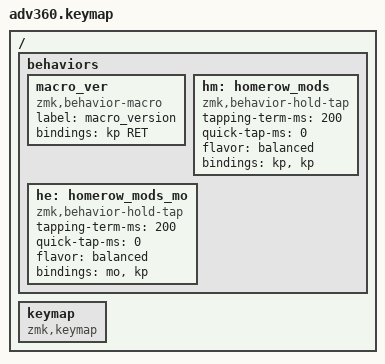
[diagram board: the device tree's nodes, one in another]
#include <behaviors.dtsi>
#include <dt-bindings/zmk/keys.h>
#include <dt-bindings/zmk/bt.h>
#include <dt-bindings/zmk/rgb.h>
#include <dt-bindings/zmk/backlight.h>

/ {
    behaviors {
      #include "macros.dtsi"
      #include "version.dtsi"
      #ifndef VERSION_MACRO
      macro_ver: macro_ver {
        compatible = "zmk,behavior-macro";
        label = "macro_version";
        #binding-cells = <0>;
        bindings = <&kp RET>;
      };
      #endif

      hm: homerow_mods {
        compatible = "zmk,behavior-hold-tap";
        #binding-cells = <2>;
        tapping-term-ms = <200>;
        quick-tap-ms = <0>;
        flavor = "balanced";
        bindings = <&kp>, <&kp>;
      };

      he: homerow_mods_mo {
        compatible = "zmk,behavior-hold-tap";
        #binding-cells = <2>;
        tapping-term-ms = <200>;
        quick-tap-ms = <0>;
        flavor = "balanced";
        bindings = <&mo>, <&kp>;
      };

    };

  #define LS(x) &hm LSHIFT x
  #define LC(x) &hm LCTRL x
  #define LA(x) &hm LALT x
  #define LG(x) &hm LGUI x
  #define SY(x, y) &he x y

  keymap {
    compatible = "zmk,keymap";
    #include "keymap.dtsi"
  };
};

/*
1 - BASE LAYER
 ╭────────────────────────────┬────────────────────────────╮
 │ 󰢤󰢤  1!  2@  3#  4$  5%  󰢤󰢤 │ 󰢤󰢤  6^  7&  8*  (9  )0  󰢤󰢤 │
 │ 󰢤󰢤   Q   W   E   R   T  󰢤󰢤 │ 󰢤󰢤   Y   U   I   O   P  󰢤󰢤 │
 │ 󰢤󰢤   A  ⌃S  ⇧D  ⌘F  ⎇G  󰢤󰢤 │ 󰢤󰢤  ⎇H  ⌘J  ⇧K  ⌃L TAB  󰢤󰢤 │
 │ 󰢤󰢤  󰢤󰢤   Z   X   C  ★V ╭───┴───╮  B   N   M ESC  󰢤󰢤  󰢤󰢤 │
 │ 󰢤󰢤  󰢤󰢤  󰢤󰢤   ←   →╭────╯       ╰────╮ ↑   ↓  󰢤󰢤  󰢤󰢤  󰢤󰢤 │
 ╰───────────────────┼────────┬────────┼───────────────────╯
                 ╭───╯ 󰢤󰢤  󰢤󰢤 │ 󰢤󰢤  󰢤󰢤 ╰───╮
                 │ BSP DEL 󰢤󰢤 │ 󰢤󰢤  CR SPC │
                 ╰───────╮ 󰢤󰢤 │ 󰢤󰢤 ╭───────╯
                         ╰────┴────╯
2 - MOD (★)

 ╭────────────────────────────┬────────────────────────────╮
 │ 󰢤󰢤  󰢤󰢤  󰢤󰢤  󰢤󰢤  󰢤󰢤  󰢤󰢤  󰢤󰢤 │ 󰢤󰢤           󰢤󰢤  󰢤󰢤  󰢤󰢤 │
 │ 󰢤󰢤  󰢤󰢤  󰢤󰢤  󰢤󰢤  󰢤󰢤  󰢤󰢤  󰢤󰢤 │ 󰢤󰢤  -_  =+  [{  ]}  󰢤󰢤  󰢤󰢤 │
 │ 󰢤󰢤  󰢤󰢤  󰢤󰢤  󰢤󰢤  󰢤󰢤  󰢤󰢤  󰢤󰢤 │ 󰢤󰢤  `~  ;:  '"  \|  󰢤󰢤  󰢤󰢤 │
 │ 󰢤󰢤  󰢤󰢤  󰢤󰢤  󰢤󰢤  󰢤󰢤  󰢤󰢤 ╭───┴───╮ ,<  .>  /?  󰢤󰢤  󰢤󰢤  󰢤󰢤 │
 │ 󰛆   󰢤󰢤  󰢤󰢤  󰢤󰢤  󰢤󰢤╭────╯       ╰────╮󰢤󰢤  󰢤󰢤  󰢤󰢤  󰢤󰢤   󰛆 │
 ╰───────────────────╯                 ╰───────────────────╯
- 󰛆 bootloader
*/
